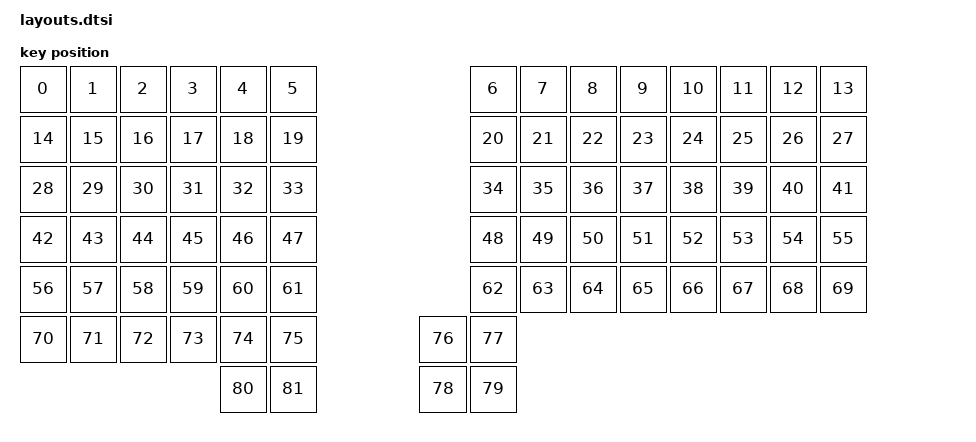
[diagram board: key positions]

#include <physical_layouts.dtsi>
/ {
    physical_layout0: physical_layout0 {
        compatible = "zmk,physical-layout";
        display-name = "Layout";
        keys
            = <&key_physical_attrs 100 100 150 100 0 0 0>
			,<&key_physical_attrs 100 100 250 100 0 0 0>
			,<&key_physical_attrs 100 100 350 100 0 0 0>
			,<&key_physical_attrs 100 100 450 100 0 0 0>
			,<&key_physical_attrs 100 100 550 100 0 0 0>
			,<&key_physical_attrs 100 100 650 100 0 0 0>
			,<&key_physical_attrs 100 100 1050 100 0 0 0>
			,<&key_physical_attrs 100 100 1150 100 0 0 0>
			,<&key_physical_attrs 100 100 1250 100 0 0 0>
			,<&key_physical_attrs 100 100 1350 100 0 0 0>
			,<&key_physical_attrs 100 100 1450 100 0 0 0>
			,<&key_physical_attrs 100 100 1550 100 0 0 0>
			,<&key_physical_attrs 100 100 1650 100 0 0 0>
			,<&key_physical_attrs 100 100 1750 100 0 0 0>
			,<&key_physical_attrs 100 100 150 200 0 0 0>
			,<&key_physical_attrs 100 100 250 200 0 0 0>
			,<&key_physical_attrs 100 100 350 200 0 0 0>
			,<&key_physical_attrs 100 100 450 200 0 0 0>
			,<&key_physical_attrs 100 100 550 200 0 0 0>
			,<&key_physical_attrs 100 100 650 200 0 0 0>
			,<&key_physical_attrs 100 100 1050 200 0 0 0>
			,<&key_physical_attrs 100 100 1150 200 0 0 0>
			,<&key_physical_attrs 100 100 1250 200 0 0 0>
			,<&key_physical_attrs 100 100 1350 200 0 0 0>
			,<&key_physical_attrs 100 100 1450 200 0 0 0>
			,<&key_physical_attrs 100 100 1550 200 0 0 0>
			,<&key_physical_attrs 100 100 1650 200 0 0 0>
			,<&key_physical_attrs 100 100 1750 200 0 0 0>
			,<&key_physical_attrs 100 100 150 300 0 0 0>
			,<&key_physical_attrs 100 100 250 300 0 0 0>
			,<&key_physical_attrs 100 100 350 300 0 0 0>
			,<&key_physical_attrs 100 100 450 300 0 0 0>
			,<&key_physical_attrs 100 100 550 300 0 0 0>
			,<&key_physical_attrs 100 100 650 300 0 0 0>
			,<&key_physical_attrs 100 100 1050 300 0 0 0>
			,<&key_physical_attrs 100 100 1150 300 0 0 0>
			,<&key_physical_attrs 100 100 1250 300 0 0 0>
			,<&key_physical_attrs 100 100 1350 300 0 0 0>
			,<&key_physical_attrs 100 100 1450 300 0 0 0>
			,<&key_physical_attrs 100 100 1550 300 0 0 0>
			,<&key_physical_attrs 100 100 1650 300 0 0 0>
			,<&key_physical_attrs 100 100 1750 300 0 0 0>
			,<&key_physical_attrs 100 100 150 400 0 0 0>
			,<&key_physical_attrs 100 100 250 400 0 0 0>
			,<&key_physical_attrs 100 100 350 400 0 0 0>
			,<&key_physical_attrs 100 100 450 400 0 0 0>
			,<&key_physical_attrs 100 100 550 400 0 0 0>
			,<&key_physical_attrs 100 100 650 400 0 0 0>
			,<&key_physical_attrs 100 100 1050 400 0 0 0>
			,<&key_physical_attrs 100 100 1150 400 0 0 0>
			,<&key_physical_attrs 100 100 1250 400 0 0 0>
			,<&key_physical_attrs 100 100 1350 400 0 0 0>
			,<&key_physical_attrs 100 100 1450 400 0 0 0>
			,<&key_physical_attrs 100 100 1550 400 0 0 0>
			,<&key_physical_attrs 100 100 1650 400 0 0 0>
			,<&key_physical_attrs 100 100 1750 400 0 0 0>
			,<&key_physical_attrs 100 100 150 500 0 0 0>
			,<&key_physical_attrs 100 100 250 500 0 0 0>
			,<&key_physical_attrs 100 100 350 500 0 0 0>
			,<&key_physical_attrs 100 100 450 500 0 0 0>
			,<&key_physical_attrs 100 100 550 500 0 0 0>
			,<&key_physical_attrs 100 100 650 500 0 0 0>
			,<&key_physical_attrs 100 100 1050 500 0 0 0>
			,<&key_physical_attrs 100 100 1150 500 0 0 0>
			,<&key_physical_attrs 100 100 1250 500 0 0 0>
			,<&key_physical_attrs 100 100 1350 500 0 0 0>
			,<&key_physical_attrs 100 100 1450 500 0 0 0>
			,<&key_physical_attrs 100 100 1550 500 0 0 0>
			,<&key_physical_attrs 100 100 1650 500 0 0 0>
			,<&key_physical_attrs 100 100 1750 500 0 0 0>
			,<&key_physical_attrs 100 100 150 600 0 0 0>
			,<&key_physical_attrs 100 100 250 600 0 0 0>
			,<&key_physical_attrs 100 100 350 600 0 0 0>
			,<&key_physical_attrs 100 100 450 600 0 0 0>
			,<&key_physical_attrs 100 100 550 600 0 0 0>
			,<&key_physical_attrs 100 100 650 600 0 0 0>
			,<&key_physical_attrs 100 100 950 600 0 0 0>
			,<&key_physical_attrs 100 100 1050 600 0 0 0>
			,<&key_physical_attrs 100 100 950 700 0 0 0>
			,<&key_physical_attrs 100 100 1050 700 0 0 0>
			,<&key_physical_attrs 100 100 550 700 0 0 0>
			,<&key_physical_attrs 100 100 650 700 0 0 0>
            ;
    };
};
    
